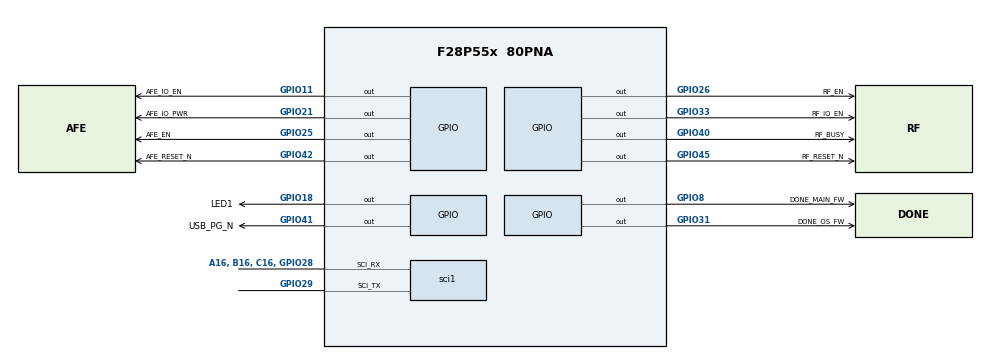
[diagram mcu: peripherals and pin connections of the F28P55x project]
/**
 *
 * @cliArgs --device "F28P55x" --part "F28P55x_80PNA" --package "80PNA" --context "system" --product "C2000WARE@26.01.00.00"
 * @versions {"tool":"1.28.1+4785"}
 */

/**
 * Import the modules used in this configuration.
 */
const led            = scripting.addModule("/driverlib/board_components/led", {}, false);
const led1           = led.addInstance();
const device_support = scripting.addModule("/driverlib/device_support.js");
const gpio           = scripting.addModule("/driverlib/gpio.js", {}, false);
const gpio2          = gpio.addInstance();
const gpio3          = gpio.addInstance();
const gpio4          = gpio.addInstance();
const gpio5          = gpio.addInstance();
const gpio6          = gpio.addInstance();
const gpio7          = gpio.addInstance();
const gpio8          = gpio.addInstance();
const gpio9          = gpio.addInstance();
const gpio10         = gpio.addInstance();
const gpio11         = gpio.addInstance();
const gpio12         = gpio.addInstance();
const gpio13         = gpio.addInstance();
const sci            = scripting.addModule("/driverlib/sci.js", {}, false);
const sci1           = sci.addInstance();
const spi            = scripting.addModule("/driverlib/spi.js", {}, false);
const spi1           = spi.addInstance();
const sysctl         = scripting.addModule("/driverlib/sysctl.js");
const CMD            = scripting.addModule("/utilities/cmd_tool/cmd_syscfg/source/CMD");
const CMD1           = CMD.addInstance();
const CMD2           = CMD.addInstance();

/**
 * Write custom configuration values to the imported modules.
 */
led1.$name                         = "LED1";
led1.gpio.writeInitialValue        = true;
led1.gpio.gpioPin.$assign          = "GPIO18";
led1.gpio.gpioPin["GPIO#"].$assign = "GPIO18, X2";

gpio2.$name                    = "AFE_EN";
gpio2.direction                = "GPIO_DIR_MODE_OUT";
gpio2.writeInitialValue        = true;
gpio2.gpioPin.$assign          = "GPIO25";
gpio2.gpioPin["GPIO#"].$assign = "GPIO25";

gpio3.$name                    = "RF_EN";
gpio3.direction                = "GPIO_DIR_MODE_OUT";
gpio3.writeInitialValue        = true;
gpio3.gpioPin.$assign          = "GPIO26";
gpio3.gpioPin["GPIO#"].$assign = "GPIO26";

gpio4.$name                    = "AFE_IO_PWR";
gpio4.direction                = "GPIO_DIR_MODE_OUT";
gpio4.writeInitialValue        = true;
gpio4.gpioPin.$assign          = "GPIO21";
gpio4.gpioPin["GPIO#"].$assign = "A18, B18, C18, GPIO21";

gpio5.$name           = "USB_PG_N";
gpio5.gpioPin.$assign = "GPIO41";

gpio6.$name = "myGPIO0";

gpio7.$name                    = "RF_IO_EN";
gpio7.direction                = "GPIO_DIR_MODE_OUT";
gpio7.writeInitialValue        = true;
gpio7.gpioPin.$assign          = "GPIO33";
gpio7.gpioPin["GPIO#"].$assign = "B24, D1, E1, GPIO33";

gpio8.$name                    = "AFE_IO_EN";
gpio8.direction                = "GPIO_DIR_MODE_OUT";
gpio8.writeInitialValue        = true;
gpio8.gpioPin.$assign          = "GPIO11";
gpio8.gpioPin["GPIO#"].$assign = "A24, D0, E0, GPIO11";

gpio9.direction                = "GPIO_DIR_MODE_OUT";
gpio9.writeInitialValue        = true;
gpio9.$name                    = "AFE_RESET_N";
gpio9.gpioPin.$assign          = "GPIO42";
gpio9.gpioPin["GPIO#"].$assign = "GPIO42";

gpio10.direction                = "GPIO_DIR_MODE_OUT";
gpio10.writeInitialValue        = true;
gpio10.$name                    = "RF_RESET_N";
gpio10.gpioPin.$assign          = "GPIO45";
gpio10.gpioPin["GPIO#"].$assign = "GPIO45";

gpio11.$name                    = "RF_BUSY";
gpio11.gpioPin.$assign          = "GPIO40";
gpio11.gpioPin["GPIO#"].$assign = "GPIO40";

gpio12.direction                = "GPIO_DIR_MODE_OUT";
gpio12.writeInitialValue        = true;
gpio12.$name                    = "DONE_OS_FW";
gpio12.gpioPin.$assign          = "GPIO31";
gpio12.gpioPin["GPIO#"].$assign = "GPIO31";

gpio13.direction                = "GPIO_DIR_MODE_OUT";
gpio13.writeInitialValue        = true;
gpio13.$name                    = "DONE_MAIN_FW";
gpio13.gpioPin.$assign          = "GPIO8";
gpio13.gpioPin["GPIO#"].$assign = "GPIO8";

sci1.$name                 = "EASY_SCIA";
sci1.sci.$assign           = "SCIA";
sci1.sci.sci_rxPin.$assign = "A16, B16, C16, GPIO28";
sci1.sci.sci_txPin.$assign = "GPIO29";
sci1.rxQual.$name          = "myGPIOQUAL4";
sci1.txQual.$name          = "myGPIOQUAL5";

spi1.$name          = "RF_SPIB";
spi1.picoQual.$name = "myGPIOQUAL0";
spi1.pociQual.$name = "myGPIOQUAL1";
spi1.clkQual.$name  = "myGPIOQUAL2";
spi1.pteQual.$name  = "myGPIOQUAL3";

CMD1.$name                    = "generic_ram_lnk";
CMD1.sectionMemory_text       = ["RAMLS0","RAMLS1","RAMLS2","RAMLS3","RAMLS8"];
CMD1.sectionMemory_bss        = ["RAMLS5"];
CMD1.sectionMemory_const      = ["RAMLS5","RAMLS6"];
CMD1.sectionMemory_data       = ["RAMLS5"];
CMD1.sectionMemory_ramfunc    = ["RAMM0"];
CMD1.sectionMemory_cinit      = ["RAMM0"];
CMD1.sectionMemory_stack      = ["RAMM1"];
CMD1.sectionMemory_init_array = ["RAMM0"];
CMD1.sectionMemory_switch     = ["RAMM0"];
CMD1.sectionMemory_sysmem     = ["RAMLS4"];

CMD2.$name                               = "generic_flash_lnk";
CMD2.sectionAlignEnable_ramfunc          = true;
CMD2.sectionAlignEnable_text             = true;
CMD2.sectionAlignEnable_binit            = true;
CMD2.sectionAlignEnable_cinit            = true;
CMD2.sectionAlignEnable_switch           = true;
CMD2.sectionAlignEnable_init_array       = true;
CMD2.sectionAlignEnable_const            = true;
CMD2.sectionAlignEnable_ovly             = true;
CMD2.sectionMemory_codestart             = "0x080000";
CMD2.sectionMemory_stack                 = ["RAMM1"];
CMD2.sectionMemory_bss                   = ["RAMLS5"];
CMD2.sectionMemory_data                  = ["RAMLS5"];
CMD2.sectionMemory_sysmem                = ["RAMLS5"];
CMD2.sectionMemory_ramfunc               = ["FLASH_BANK0"];
CMD2.sectionMemory_text                  = ["FLASH_BANK0","FLASH_BANK1"];
CMD2.sectionMemory_binit                 = ["FLASH_BANK0"];
CMD2.sectionMemory_cinit                 = ["FLASH_BANK0"];
CMD2.sectionMemory_switch                = ["FLASH_BANK0"];
CMD2.sectionMemory_init_array            = ["FLASH_BANK0"];
CMD2.sectionMemory_const                 = ["FLASH_BANK0"];
CMD2.sectionMemory_ovly                  = ["FLASH_BANK0"];
CMD2.sectionRunFromDifferentAddr_ramfunc = true;
CMD2.sectionRun_ramfunc                  = ["RAMLS0"];
CMD2.sectionBinit_ramfunc                = false;

/**
 * Pinmux solution for unlocked pins/peripherals. This ensures that minor changes to the automatic solver in a future
 * version of the tool will not impact the pinmux you originally saw.  These lines can be completely deleted in order to
 * re-solve from scratch.
 */
gpio5.gpioPin["GPIO#"].$suggestSolution = "GPIO41";
gpio6.gpioPin.$suggestSolution          = "GPIO0";
gpio6.gpioPin["GPIO#"].$suggestSolution = "GPIO0";
spi1.spi.$suggestSolution               = "SPIA";
spi1.spi.spi_picoPin.$suggestSolution   = "A2, B6, C9, PGA1_INP, GPIO224";
spi1.spi.spi_pociPin.$suggestSolution   = "A19, B19, C19, GPIO13";
spi1.spi.spi_clkPin.$suggestSolution    = "A20, B20, C20, GPIO12";
spi1.spi.spi_ptePin.$suggestSolution    = "A3, B3, PGA2_INP, C5, GPIO242";
